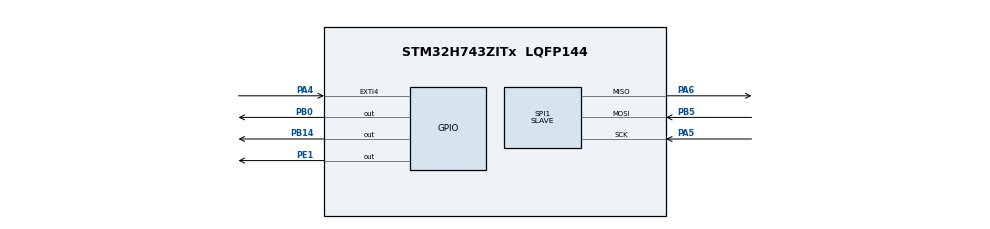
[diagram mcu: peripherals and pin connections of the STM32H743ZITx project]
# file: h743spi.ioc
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CORTEX_M7.CPU_DCache=Enabled
CORTEX_M7.CPU_ICache=Enabled
Dma.Request0=SPI1_RX
Dma.Request1=SPI1_TX
Dma.SPI1_RX.0.Direction=DMA_PERIPH_TO_MEMORY
Dma.SPI1_RX.0.EventEnable=DISABLE
Dma.SPI1_RX.0.FIFOMode=DMA_FIFOMODE_DISABLE
Dma.SPI1_RX.0.Instance=DMA1_Stream0
Dma.SPI1_RX.0.MemDataAlignment=DMA_MDATAALIGN_BYTE
Dma.SPI1_RX.0.MemInc=DMA_MINC_ENABLE
Dma.SPI1_RX.0.Mode=DMA_NORMAL
Dma.SPI1_RX.0.PeriphDataAlignment=DMA_PDATAALIGN_BYTE
Dma.SPI1_RX.0.PeriphInc=DMA_PINC_DISABLE
Dma.SPI1_RX.0.Polarity=HAL_DMAMUX_REQ_GEN_RISING
Dma.SPI1_RX.0.Priority=DMA_PRIORITY_LOW
Dma.SPI1_RX.0.RequestNumber=1
Dma.SPI1_RX.0.SignalID=NONE
Dma.SPI1_RX.0.SyncEnable=DISABLE
Dma.SPI1_RX.0.SyncPolarity=HAL_DMAMUX_SYNC_NO_EVENT
Dma.SPI1_RX.0.SyncRequestNumber=1
Dma.SPI1_RX.0.SyncSignalID=NONE
Dma.SPI1_TX.1.Direction=DMA_MEMORY_TO_PERIPH
Dma.SPI1_TX.1.EventEnable=DISABLE
Dma.SPI1_TX.1.FIFOMode=DMA_FIFOMODE_DISABLE
Dma.SPI1_TX.1.Instance=DMA1_Stream1
Dma.SPI1_TX.1.MemDataAlignment=DMA_MDATAALIGN_BYTE
Dma.SPI1_TX.1.MemInc=DMA_MINC_ENABLE
Dma.SPI1_TX.1.Mode=DMA_NORMAL
Dma.SPI1_TX.1.PeriphDataAlignment=DMA_PDATAALIGN_BYTE
Dma.SPI1_TX.1.PeriphInc=DMA_PINC_DISABLE
Dma.SPI1_TX.1.Polarity=HAL_DMAMUX_REQ_GEN_RISING
Dma.SPI1_TX.1.Priority=DMA_PRIORITY_LOW
Dma.SPI1_TX.1.RequestNumber=1
Dma.SPI1_TX.1.SignalID=NONE
Dma.SPI1_TX.1.SyncEnable=DISABLE
Dma.SPI1_TX.1.SyncPolarity=HAL_DMAMUX_SYNC_NO_EVENT
Dma.SPI1_TX.1.SyncRequestNumber=1
Dma.SPI1_TX.1.SyncSignalID=NONE
Mcu.Family=STM32H7
Mcu.Name=STM32H743ZITx
Mcu.Package=LQFP144
NVIC.DMA1_Stream0_IRQn=true\:0\:0\:false\:false\:true\:false\:false
NVIC.EXTI4_IRQn=true\:0\:0\:false\:false\:true\:true\:false
NVIC.PriorityGroup=NVIC_PRIORITYGROUP_4
NVIC.SPI1_IRQn=true\:0\:0\:false\:false\:false\:false\:false
PA4.GPIO_ModeDefaultEXTI=GPIO_MODE_IT_FALLING
PA4.GPIO_PuPd=GPIO_NOPULL
PA4.Signal=GPXTI4
PA5.Mode=Full_Duplex_Slave
PA5.Signal=SPI1_SCK
PA6.Mode=Full_Duplex_Slave
PA6.Signal=SPI1_MISO
PB0.Signal=GPIO_Output
PB14.Signal=GPIO_Output
PB5.Mode=Full_Duplex_Slave
PB5.Signal=SPI1_MOSI
PE1.Signal=GPIO_Output
PH0-OSC_IN\ (PH0).Mode=HSE-External-Oscillator
PH0-OSC_IN\ (PH0).Signal=RCC_OSC_IN
PH1-OSC_OUT\ (PH1).Mode=HSE-External-Oscillator
PH1-OSC_OUT\ (PH1).Signal=RCC_OSC_OUT
ProjectManager.HeapSize=0x4000
ProjectManager.StackSize=0x8000
ProjectManager.TargetToolchain=STM32CubeIDE
RCC.ADCFreq_Value=16125000
RCC.APB1Freq_Value=120000000
RCC.APB2Freq_Value=120000000
RCC.APB3Freq_Value=120000000
RCC.APB4Freq_Value=120000000
RCC.CortexFreq_Value=480000000
RCC.D1PPRE=RCC_APB3_DIV2
RCC.D2PPRE1=RCC_APB1_DIV2
RCC.D2PPRE2=RCC_APB2_DIV2
RCC.D3PPRE=RCC_APB4_DIV2
RCC.DIVM1=4
RCC.DIVN1=480
RCC.HCLKFreq_Value=240000000
RCC.HPRE=RCC_HCLK_DIV2
RCC.HSE_VALUE=8000000
RCC.PLLSourceVirtual=RCC_PLLSOURCE_HSE
RCC.SYSCLKFreq_VALUE=480000000
RCC.SYSCLKSource=RCC_SYSCLKSOURCE_PLLCLK
RCC.USBFreq_Value=480000000
SPI1.CLKPhase=SPI_PHASE_2EDGE
SPI1.DataSize=SPI_DATASIZE_8BIT
SPI1.Direction=SPI_DIRECTION_2LINES
SPI1.Mode=SPI_MODE_SLAVE
SPI1.VirtualType=VM_SLAVE
board=custom

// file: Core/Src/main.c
/* USER CODE BEGIN Header */
/**
  ******************************************************************************
  * @file           : main.c
  * @brief          : Main program body
  ******************************************************************************
  * @attention
  *
  * <h2><center>&copy; Copyright (c) 2020 STMicroelectronics.
  * All rights reserved.</center></h2>
  *
  * This software component is licensed by ST under BSD 3-Clause license,
  * the "License"; You may not use this file except in compliance with the
  * License. You may obtain a copy of the License at:
  *                        opensource.org/licenses/BSD-3-Clause
  *
  ******************************************************************************
  */
/* USER CODE END Header */
#include "main.h"

void SystemClock_Config(void);
static void MX_GPIO_Init(void);
static void MX_DMA_Init(void);
static void MX_SPI1_Init(void);

/* USER CODE BEGIN 0 */
void EXTI4_IRQHandlerCB(void)
{
  LL_GPIO_TogglePin(GPIOB, LL_GPIO_PIN_14);
}

void DMA1_Stream0_IRQHandlerCB(void)
{
}

/* USER CODE END 0 */

int main(void)
{

  /* Enable I-Cache---------------------------------------------------------*/
  SCB_EnableICache();

  /* Enable D-Cache---------------------------------------------------------*/
  SCB_EnableDCache();

  /* MCU Configuration--------------------------------------------------------*/

  /* Reset of all peripherals, Initializes the Flash interface and the Systick. */

  LL_APB4_GRP1_EnableClock(LL_APB4_GRP1_PERIPH_SYSCFG);

  NVIC_SetPriorityGrouping(NVIC_PRIORITYGROUP_4);

  /* System interrupt init*/

  /* Configure the system clock */
  SystemClock_Config();

  /* Initialize all configured peripherals */
  MX_GPIO_Init();
  MX_DMA_Init();
  MX_SPI1_Init();

  /* Infinite loop */
  while (1)
  {

    /* USER CODE BEGIN 3 */
    LL_GPIO_TogglePin(GPIOB, LL_GPIO_PIN_0);
    LL_GPIO_TogglePin(GPIOE, LL_GPIO_PIN_1);
    LL_mDelay(200);
  }
  /* USER CODE END 3 */
}

void SystemClock_Config(void)
{
  LL_FLASH_SetLatency(LL_FLASH_LATENCY_4);
  while(LL_FLASH_GetLatency()!= LL_FLASH_LATENCY_4)
  {
  }
  LL_PWR_ConfigSupply(LL_PWR_LDO_SUPPLY);
  LL_PWR_SetRegulVoltageScaling(LL_PWR_REGU_VOLTAGE_SCALE0);
  LL_RCC_HSE_Enable();

   /* Wait till HSE is ready */
  while(LL_RCC_HSE_IsReady() != 1)
  {

  }
  LL_RCC_PLL_SetSource(LL_RCC_PLLSOURCE_HSE);
  LL_RCC_PLL1P_Enable();
  LL_RCC_PLL1Q_Enable();
  LL_RCC_PLL1_SetVCOInputRange(LL_RCC_PLLINPUTRANGE_2_4);
  LL_RCC_PLL1_SetVCOOutputRange(LL_RCC_PLLVCORANGE_WIDE);
  LL_RCC_PLL1_SetM(4);
  LL_RCC_PLL1_SetN(480);
  LL_RCC_PLL1_SetP(2);
  LL_RCC_PLL1_SetQ(2);
  LL_RCC_PLL1_SetR(2);
  LL_RCC_PLL1_Enable();

   /* Wait till PLL is ready */
  while(LL_RCC_PLL1_IsReady() != 1)
  {
  }

   /* Intermediate AHB prescaler 2 when target frequency clock is higher than 80 MHz */
   LL_RCC_SetAHBPrescaler(LL_RCC_AHB_DIV_2);

  LL_RCC_SetSysClkSource(LL_RCC_SYS_CLKSOURCE_PLL1);
  LL_RCC_SetSysPrescaler(LL_RCC_SYSCLK_DIV_1);
  LL_RCC_SetAHBPrescaler(LL_RCC_AHB_DIV_2);
  LL_RCC_SetAPB1Prescaler(LL_RCC_APB1_DIV_2);
  LL_RCC_SetAPB2Prescaler(LL_RCC_APB2_DIV_2);
  LL_RCC_SetAPB3Prescaler(LL_RCC_APB3_DIV_2);
  LL_RCC_SetAPB4Prescaler(LL_RCC_APB4_DIV_2);

  LL_Init1msTick(480000000);

  LL_SetSystemCoreClock(480000000);
  LL_RCC_SetSPIClockSource(LL_RCC_SPI123_CLKSOURCE_PLL1Q);
}

static void MX_SPI1_Init(void)
{

  LL_SPI_InitTypeDef SPI_InitStruct = {0};

  LL_GPIO_InitTypeDef GPIO_InitStruct = {0};

  /* Peripheral clock enable */
  LL_APB2_GRP1_EnableClock(LL_APB2_GRP1_PERIPH_SPI1);

  LL_AHB4_GRP1_EnableClock(LL_AHB4_GRP1_PERIPH_GPIOA);
  LL_AHB4_GRP1_EnableClock(LL_AHB4_GRP1_PERIPH_GPIOB);
  /**SPI1 GPIO Configuration
  PA5   ------> SPI1_SCK
  PA6   ------> SPI1_MISO
  PB5   ------> SPI1_MOSI
  */
  GPIO_InitStruct.Pin = LL_GPIO_PIN_5|LL_GPIO_PIN_6;
  GPIO_InitStruct.Mode = LL_GPIO_MODE_ALTERNATE;
  GPIO_InitStruct.Speed = LL_GPIO_SPEED_FREQ_LOW;
  GPIO_InitStruct.OutputType = LL_GPIO_OUTPUT_PUSHPULL;
  GPIO_InitStruct.Pull = LL_GPIO_PULL_NO;
  GPIO_InitStruct.Alternate = LL_GPIO_AF_5;
  LL_GPIO_Init(GPIOA, &GPIO_InitStruct);

  GPIO_InitStruct.Pin = LL_GPIO_PIN_5;
  GPIO_InitStruct.Mode = LL_GPIO_MODE_ALTERNATE;
  GPIO_InitStruct.Speed = LL_GPIO_SPEED_FREQ_LOW;
  GPIO_InitStruct.OutputType = LL_GPIO_OUTPUT_PUSHPULL;
  GPIO_InitStruct.Pull = LL_GPIO_PULL_NO;
  GPIO_InitStruct.Alternate = LL_GPIO_AF_5;
  LL_GPIO_Init(GPIOB, &GPIO_InitStruct);

  /* SPI1 DMA Init */

  /* SPI1_RX Init */
  LL_DMA_SetPeriphRequest(DMA1, LL_DMA_STREAM_0, LL_DMAMUX1_REQ_SPI1_RX);

  LL_DMA_SetDataTransferDirection(DMA1, LL_DMA_STREAM_0, LL_DMA_DIRECTION_PERIPH_TO_MEMORY);

  LL_DMA_SetStreamPriorityLevel(DMA1, LL_DMA_STREAM_0, LL_DMA_PRIORITY_LOW);

  LL_DMA_SetMode(DMA1, LL_DMA_STREAM_0, LL_DMA_MODE_NORMAL);

  LL_DMA_SetPeriphIncMode(DMA1, LL_DMA_STREAM_0, LL_DMA_PERIPH_NOINCREMENT);

  LL_DMA_SetMemoryIncMode(DMA1, LL_DMA_STREAM_0, LL_DMA_MEMORY_INCREMENT);

  LL_DMA_SetPeriphSize(DMA1, LL_DMA_STREAM_0, LL_DMA_PDATAALIGN_BYTE);

  LL_DMA_SetMemorySize(DMA1, LL_DMA_STREAM_0, LL_DMA_MDATAALIGN_BYTE);

  LL_DMA_DisableFifoMode(DMA1, LL_DMA_STREAM_0);

  /* SPI1_TX Init */
  LL_DMA_SetPeriphRequest(DMA1, LL_DMA_STREAM_1, LL_DMAMUX1_REQ_SPI1_TX);

  LL_DMA_SetDataTransferDirection(DMA1, LL_DMA_STREAM_1, LL_DMA_DIRECTION_MEMORY_TO_PERIPH);

  LL_DMA_SetStreamPriorityLevel(DMA1, LL_DMA_STREAM_1, LL_DMA_PRIORITY_LOW);

  LL_DMA_SetMode(DMA1, LL_DMA_STREAM_1, LL_DMA_MODE_NORMAL);

  LL_DMA_SetPeriphIncMode(DMA1, LL_DMA_STREAM_1, LL_DMA_PERIPH_NOINCREMENT);

  LL_DMA_SetMemoryIncMode(DMA1, LL_DMA_STREAM_1, LL_DMA_MEMORY_INCREMENT);

  LL_DMA_SetPeriphSize(DMA1, LL_DMA_STREAM_1, LL_DMA_PDATAALIGN_BYTE);

  LL_DMA_SetMemorySize(DMA1, LL_DMA_STREAM_1, LL_DMA_MDATAALIGN_BYTE);

  LL_DMA_DisableFifoMode(DMA1, LL_DMA_STREAM_1);

  /* SPI1 interrupt Init */
  NVIC_SetPriority(SPI1_IRQn, NVIC_EncodePriority(NVIC_GetPriorityGrouping(),0, 0));
  NVIC_EnableIRQ(SPI1_IRQn);

  /* SPI1 parameter configuration*/
  SPI_InitStruct.TransferDirection = LL_SPI_FULL_DUPLEX;
  SPI_InitStruct.Mode = LL_SPI_MODE_SLAVE;
  SPI_InitStruct.DataWidth = LL_SPI_DATAWIDTH_8BIT;
  SPI_InitStruct.ClockPolarity = LL_SPI_POLARITY_LOW;
  SPI_InitStruct.ClockPhase = LL_SPI_PHASE_2EDGE;
  SPI_InitStruct.NSS = LL_SPI_NSS_SOFT;
  SPI_InitStruct.BitOrder = LL_SPI_MSB_FIRST;
  SPI_InitStruct.CRCCalculation = LL_SPI_CRCCALCULATION_DISABLE;
  SPI_InitStruct.CRCPoly = 0x0;
  LL_SPI_Init(SPI1, &SPI_InitStruct);
  LL_SPI_SetStandard(SPI1, LL_SPI_PROTOCOL_MOTOROLA);
  LL_SPI_DisableNSSPulseMgt(SPI1);
  /* USER CODE BEGIN SPI1_Init 2 */
  NVIC_DisableIRQ(SPI1_IRQn);
  LL_SPI_Enable(SPI1);
  LL_SPI_EnableDMAReq_RX(SPI1);
  LL_SPI_EnableDMAReq_TX(SPI1);
  /* USER CODE END SPI1_Init 2 */

}

static void MX_DMA_Init(void)
{

  /* Init with LL driver */
  /* DMA controller clock enable */
  LL_AHB1_GRP1_EnableClock(LL_AHB1_GRP1_PERIPH_DMA1);

  /* DMA interrupt init */
  /* DMA1_Stream0_IRQn interrupt configuration */
  NVIC_SetPriority(DMA1_Stream0_IRQn, NVIC_EncodePriority(NVIC_GetPriorityGrouping(),0, 0));
  NVIC_EnableIRQ(DMA1_Stream0_IRQn);

}

static void MX_GPIO_Init(void)
{
  LL_EXTI_InitTypeDef EXTI_InitStruct = {0};
  LL_GPIO_InitTypeDef GPIO_InitStruct = {0};

  /* GPIO Ports Clock Enable */
  LL_AHB4_GRP1_EnableClock(LL_AHB4_GRP1_PERIPH_GPIOH);
  LL_AHB4_GRP1_EnableClock(LL_AHB4_GRP1_PERIPH_GPIOA);
  LL_AHB4_GRP1_EnableClock(LL_AHB4_GRP1_PERIPH_GPIOB);
  LL_AHB4_GRP1_EnableClock(LL_AHB4_GRP1_PERIPH_GPIOE);

  /**/
  LL_GPIO_ResetOutputPin(GPIOB, LL_GPIO_PIN_0|LL_GPIO_PIN_14);

  /**/
  LL_GPIO_ResetOutputPin(GPIOE, LL_GPIO_PIN_1);

  /**/
  LL_SYSCFG_SetEXTISource(LL_SYSCFG_EXTI_PORTA, LL_SYSCFG_EXTI_LINE4);

  /**/
  EXTI_InitStruct.Line_0_31 = LL_EXTI_LINE_4;
  EXTI_InitStruct.Line_32_63 = LL_EXTI_LINE_NONE;
  EXTI_InitStruct.Line_64_95 = LL_EXTI_LINE_NONE;
  EXTI_InitStruct.LineCommand = ENABLE;
  EXTI_InitStruct.Mode = LL_EXTI_MODE_IT;
  EXTI_InitStruct.Trigger = LL_EXTI_TRIGGER_FALLING;
  LL_EXTI_Init(&EXTI_InitStruct);

  /**/
  LL_GPIO_SetPinPull(GPIOA, LL_GPIO_PIN_4, LL_GPIO_PULL_NO);

  /**/
  GPIO_InitStruct.Pin = LL_GPIO_PIN_0|LL_GPIO_PIN_14;
  GPIO_InitStruct.Mode = LL_GPIO_MODE_OUTPUT;
  GPIO_InitStruct.Speed = LL_GPIO_SPEED_FREQ_LOW;
  GPIO_InitStruct.OutputType = LL_GPIO_OUTPUT_PUSHPULL;
  GPIO_InitStruct.Pull = LL_GPIO_PULL_NO;
  LL_GPIO_Init(GPIOB, &GPIO_InitStruct);

  /**/
  GPIO_InitStruct.Pin = LL_GPIO_PIN_1;
  GPIO_InitStruct.Mode = LL_GPIO_MODE_OUTPUT;
  GPIO_InitStruct.Speed = LL_GPIO_SPEED_FREQ_LOW;
  GPIO_InitStruct.OutputType = LL_GPIO_OUTPUT_PUSHPULL;
  GPIO_InitStruct.Pull = LL_GPIO_PULL_NO;
  LL_GPIO_Init(GPIOE, &GPIO_InitStruct);

  /* EXTI interrupt init*/
  NVIC_SetPriority(EXTI4_IRQn, NVIC_EncodePriority(NVIC_GetPriorityGrouping(),0, 0));
  NVIC_EnableIRQ(EXTI4_IRQn);

}

void Error_Handler(void)
{
}

/************************ (C) COPYRIGHT STMicroelectronics *****END OF FILE****/
